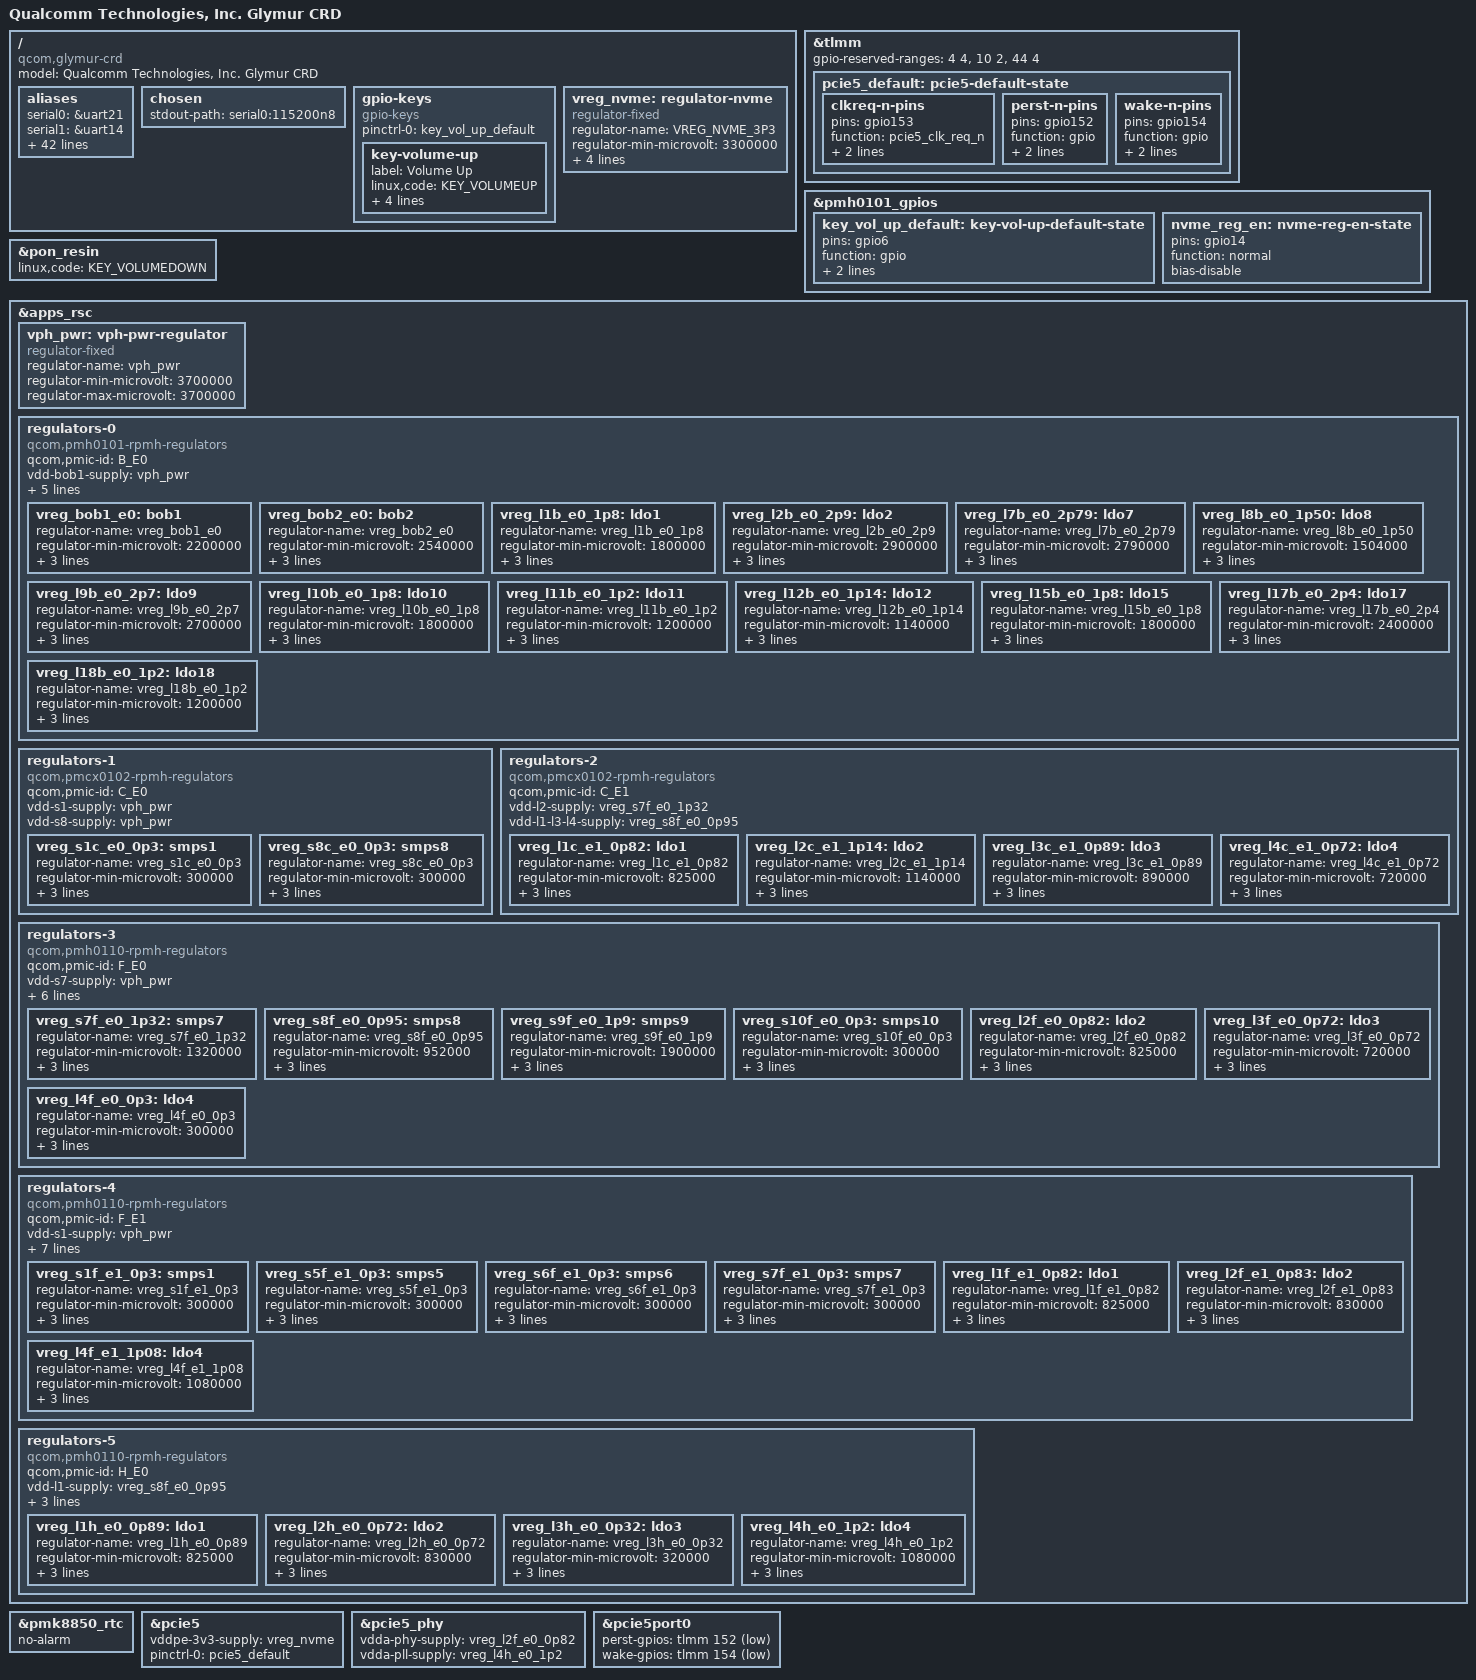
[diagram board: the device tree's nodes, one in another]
// SPDX-License-Identifier: GPL-2.0-only
/*
 * Copyright (c) Qualcomm Technologies, Inc. and/or its subsidiaries.
 */

/dts-v1/;

#include "glymur.dtsi"
#include "glymur-pmics.dtsi"
#include <dt-bindings/regulator/qcom,rpmh-regulator.h>

/ {
	model = "Qualcomm Technologies, Inc. Glymur CRD";
	compatible = "qcom,glymur-crd", "qcom,glymur";

	aliases {
		serial0 = &uart21;
		serial1 = &uart14;
		i2c0 = &i2c16;
		i2c1 = &i2c17;
		i2c2 = &i2c18;
		i2c3 = &i2c19;
		i2c4 = &i2c20;
		i2c5 = &i2c22;
		i2c6 = &i2c23;
		i2c7 = &i2c8;
		i2c8 = &i2c9;
		i2c9 = &i2c10;
		i2c10 = &i2c11;
		i2c11 = &i2c12;
		i2c12 = &i2c13;
		i2c13 = &i2c15;
		i2c14 = &i2c0;
		i2c15 = &i2c1;
		i2c16 = &i2c2;
		i2c17 = &i2c3;
		i2c18 = &i2c4;
		i2c19 = &i2c5;
		i2c20 = &i2c6;
		spi0 = &spi16;
		spi1 = &spi17;
		spi2 = &spi18;
		spi3 = &spi19;
		spi4 = &spi20;
		spi5 = &spi22;
		spi6 = &spi23;
		spi7 = &spi8;
		spi8 = &spi9;
		spi9 = &spi10;
		spi10 = &spi11;
		spi11 = &spi12;
		spi12 = &spi13;
		spi13 = &spi15;
		spi14 = &spi0;
		spi15 = &spi1;
		spi16 = &spi2;
		spi17 = &spi3;
		spi18 = &spi4;
		spi19 = &spi5;
		spi20 = &spi6;
	};

	chosen {
		stdout-path = "serial0:115200n8";
	};

	gpio-keys {
		compatible = "gpio-keys";

		pinctrl-0 = <&key_vol_up_default>;
		pinctrl-names = "default";

		key-volume-up {
			label = "Volume Up";
			linux,code = <KEY_VOLUMEUP>;
			gpios = <&pmh0101_gpios 6 GPIO_ACTIVE_LOW>;
			debounce-interval = <15>;
			linux,can-disable;
			wakeup-source;
		};
	};

	vreg_nvme: regulator-nvme {
		compatible = "regulator-fixed";

		regulator-name = "VREG_NVME_3P3";
		regulator-min-microvolt = <3300000>;
		regulator-max-microvolt = <3300000>;

		gpio = <&pmh0101_gpios 14 GPIO_ACTIVE_HIGH>;
		enable-active-high;

		pinctrl-0 = <&nvme_reg_en>;
		pinctrl-names = "default";
	};
};

&tlmm {
	gpio-reserved-ranges = <4 4>, <10 2>, <44 4>; /*Security SPI (TPM)*/
};

&pmh0101_gpios {
	key_vol_up_default: key-vol-up-default-state {
		pins = "gpio6";
		function = "gpio";
		output-disable;
		bias-pull-up;
	};
};

&pon_resin {
	linux,code = <KEY_VOLUMEDOWN>;
	status = "okay";
};

&apps_rsc {

	vph_pwr: vph-pwr-regulator {
		compatible = "regulator-fixed";
		regulator-name = "vph_pwr";
		regulator-min-microvolt = <3700000>;
		regulator-max-microvolt = <3700000>;
	};

	regulators-0 {
		compatible = "qcom,pmh0101-rpmh-regulators";
		qcom,pmic-id = "B_E0";

		vdd-bob1-supply = <&vph_pwr>;
		vdd-bob2-supply = <&vph_pwr>;
		vdd-l1-l10-l15-supply = <&vreg_s9f_e0_1p9>;
		vdd-l2-l7-l8-l9-l16-supply = <&vreg_bob1_e0>;
		vdd-l11-l12-l18-supply = <&vreg_s7f_e0_1p32>;
		vdd-l17-supply = <&vreg_bob2_e0>;

		vreg_bob1_e0: bob1 {
			regulator-name = "vreg_bob1_e0";
			regulator-min-microvolt = <2200000>;
			regulator-max-microvolt = <4224000>;
			regulator-initial-mode = <RPMH_REGULATOR_MODE_AUTO>;
		};

		vreg_bob2_e0: bob2 {
			regulator-name = "vreg_bob2_e0";
			regulator-min-microvolt = <2540000>;
			regulator-max-microvolt = <3600000>;
			regulator-initial-mode = <RPMH_REGULATOR_MODE_AUTO>;
		};

		vreg_l1b_e0_1p8: ldo1 {
			regulator-name = "vreg_l1b_e0_1p8";
			regulator-min-microvolt = <1800000>;
			regulator-max-microvolt = <1800000>;
			regulator-initial-mode = <RPMH_REGULATOR_MODE_HPM>;
		};

		vreg_l2b_e0_2p9: ldo2 {
			regulator-name = "vreg_l2b_e0_2p9";
			regulator-min-microvolt = <2900000>;
			regulator-max-microvolt = <3300000>;
			regulator-initial-mode = <RPMH_REGULATOR_MODE_HPM>;
		};

		vreg_l7b_e0_2p79: ldo7 {
			regulator-name = "vreg_l7b_e0_2p79";
			regulator-min-microvolt = <2790000>;
			regulator-max-microvolt = <3300000>;
			regulator-initial-mode = <RPMH_REGULATOR_MODE_HPM>;
		};

		vreg_l8b_e0_1p50: ldo8 {
			regulator-name = "vreg_l8b_e0_1p50";
			regulator-min-microvolt = <1504000>;
			regulator-max-microvolt = <3544000>;
			regulator-initial-mode = <RPMH_REGULATOR_MODE_HPM>;
		};

		vreg_l9b_e0_2p7: ldo9 {
			regulator-name = "vreg_l9b_e0_2p7";
			regulator-min-microvolt = <2700000>;
			regulator-max-microvolt = <3300000>;
			regulator-initial-mode = <RPMH_REGULATOR_MODE_HPM>;
		};

		vreg_l10b_e0_1p8: ldo10 {
			regulator-name = "vreg_l10b_e0_1p8";
			regulator-min-microvolt = <1800000>;
			regulator-max-microvolt = <1800000>;
			regulator-initial-mode = <RPMH_REGULATOR_MODE_HPM>;
		};

		vreg_l11b_e0_1p2: ldo11 {
			regulator-name = "vreg_l11b_e0_1p2";
			regulator-min-microvolt = <1200000>;
			regulator-max-microvolt = <1200000>;
			regulator-initial-mode = <RPMH_REGULATOR_MODE_HPM>;
		};

		vreg_l12b_e0_1p14: ldo12 {
			regulator-name = "vreg_l12b_e0_1p14";
			regulator-min-microvolt = <1140000>;
			regulator-max-microvolt = <1260000>;
			regulator-initial-mode = <RPMH_REGULATOR_MODE_HPM>;
		};

		vreg_l15b_e0_1p8: ldo15 {
			regulator-name = "vreg_l15b_e0_1p8";
			regulator-min-microvolt = <1800000>;
			regulator-max-microvolt = <1800000>;
			regulator-initial-mode = <RPMH_REGULATOR_MODE_HPM>;
		};

		vreg_l17b_e0_2p4: ldo17 {
			regulator-name = "vreg_l17b_e0_2p4";
			regulator-min-microvolt = <2400000>;
			regulator-max-microvolt = <2700000>;
			regulator-initial-mode = <RPMH_REGULATOR_MODE_HPM>;
		};

		vreg_l18b_e0_1p2: ldo18 {
			regulator-name = "vreg_l18b_e0_1p2";
			regulator-min-microvolt = <1200000>;
			regulator-max-microvolt = <1200000>;
			regulator-initial-mode = <RPMH_REGULATOR_MODE_HPM>;
		};
	};

	regulators-1 {
		compatible = "qcom,pmcx0102-rpmh-regulators";
		qcom,pmic-id = "C_E0";
		vdd-s1-supply = <&vph_pwr>;
		vdd-s8-supply = <&vph_pwr>;

		vreg_s1c_e0_0p3: smps1 {
			regulator-name = "vreg_s1c_e0_0p3";
			regulator-min-microvolt = <300000>;
			regulator-max-microvolt = <1200000>;
			regulator-initial-mode = <RPMH_REGULATOR_MODE_HPM>;
		};

		vreg_s8c_e0_0p3: smps8 {
			regulator-name = "vreg_s8c_e0_0p3";
			regulator-min-microvolt = <300000>;
			regulator-max-microvolt = <1200000>;
			regulator-initial-mode = <RPMH_REGULATOR_MODE_HPM>;
		};
	};

	regulators-2 {
		compatible = "qcom,pmcx0102-rpmh-regulators";
		qcom,pmic-id = "C_E1";

		vdd-l2-supply = <&vreg_s7f_e0_1p32>;
		vdd-l1-l3-l4-supply = <&vreg_s8f_e0_0p95>;

		vreg_l1c_e1_0p82: ldo1 {
			regulator-name = "vreg_l1c_e1_0p82";
			regulator-min-microvolt = <825000>;
			regulator-max-microvolt = <958000>;
			regulator-initial-mode = <RPMH_REGULATOR_MODE_HPM>;
		};

		vreg_l2c_e1_1p14: ldo2 {
			regulator-name = "vreg_l2c_e1_1p14";
			regulator-min-microvolt = <1140000>;
			regulator-max-microvolt = <1300000>;
			regulator-initial-mode = <RPMH_REGULATOR_MODE_HPM>;
		};

		vreg_l3c_e1_0p89: ldo3 {
			regulator-name = "vreg_l3c_e1_0p89";
			regulator-min-microvolt = <890000>;
			regulator-max-microvolt = <980000>;
			regulator-initial-mode = <RPMH_REGULATOR_MODE_HPM>;
		};

		vreg_l4c_e1_0p72: ldo4 {
			regulator-name = "vreg_l4c_e1_0p72";
			regulator-min-microvolt = <720000>;
			regulator-max-microvolt = <980000>;
			regulator-initial-mode = <RPMH_REGULATOR_MODE_HPM>;
		};
	};

	regulators-3 {
		compatible = "qcom,pmh0110-rpmh-regulators";
		qcom,pmic-id = "F_E0";
		vdd-s7-supply = <&vph_pwr>;
		vdd-s8-supply = <&vph_pwr>;
		vdd-s9-supply = <&vph_pwr>;
		vdd-s10-supply = <&vph_pwr>;
		vdd-l2-supply = <&vreg_s8f_e0_0p95>;
		vdd-l3-supply = <&vreg_s8f_e0_0p95>;
		vdd-l4-supply = <&vreg_s8f_e0_0p95>;

		vreg_s7f_e0_1p32: smps7 {
			regulator-name = "vreg_s7f_e0_1p32";
			regulator-min-microvolt = <1320000>;
			regulator-max-microvolt = <1352000>;
			regulator-initial-mode = <RPMH_REGULATOR_MODE_HPM>;
		};

		vreg_s8f_e0_0p95: smps8 {
			regulator-name = "vreg_s8f_e0_0p95";
			regulator-min-microvolt = <952000>;
			regulator-max-microvolt = <1200000>;
			regulator-initial-mode = <RPMH_REGULATOR_MODE_HPM>;
		};

		vreg_s9f_e0_1p9: smps9 {
			regulator-name = "vreg_s9f_e0_1p9";
			regulator-min-microvolt = <1900000>;
			regulator-max-microvolt = <2000000>;
			regulator-initial-mode = <RPMH_REGULATOR_MODE_HPM>;
		};

		vreg_s10f_e0_0p3: smps10 {
			regulator-name = "vreg_s10f_e0_0p3";
			regulator-min-microvolt = <300000>;
			regulator-max-microvolt = <1200000>;
			regulator-initial-mode = <RPMH_REGULATOR_MODE_HPM>;
		};

		vreg_l2f_e0_0p82: ldo2 {
			regulator-name = "vreg_l2f_e0_0p82";
			regulator-min-microvolt = <825000>;
			regulator-max-microvolt = <980000>;
			regulator-initial-mode = <RPMH_REGULATOR_MODE_HPM>;
		};

		vreg_l3f_e0_0p72: ldo3 {
			regulator-name = "vreg_l3f_e0_0p72";
			regulator-min-microvolt = <720000>;
			regulator-max-microvolt = <980000>;
			regulator-initial-mode = <RPMH_REGULATOR_MODE_HPM>;
		};

		vreg_l4f_e0_0p3: ldo4 {
			regulator-name = "vreg_l4f_e0_0p3";
			regulator-min-microvolt = <300000>;
			regulator-max-microvolt = <1200000>;
			regulator-initial-mode = <RPMH_REGULATOR_MODE_HPM>;
		};
	};

	regulators-4 {
		compatible = "qcom,pmh0110-rpmh-regulators";
		qcom,pmic-id = "F_E1";
		vdd-s1-supply = <&vph_pwr>;
		vdd-s3-supply = <&vph_pwr>;
		vdd-s5-supply = <&vph_pwr>;
		vdd-s6-supply = <&vph_pwr>;
		vdd-s7-supply = <&vph_pwr>;
		vdd-l1-supply = <&vreg_s8f_e0_0p95>;
		vdd-l2-supply = <&vreg_s8f_e0_0p95>;
		vdd-l4-supply = <&vreg_s8f_e0_0p95>;

		vreg_s1f_e1_0p3: smps1 {
			regulator-name = "vreg_s1f_e1_0p3";
			regulator-min-microvolt = <300000>;
			regulator-max-microvolt = <1200000>;
			regulator-initial-mode = <RPMH_REGULATOR_MODE_HPM>;
		};

		vreg_s5f_e1_0p3: smps5 {
			regulator-name = "vreg_s5f_e1_0p3";
			regulator-min-microvolt = <300000>;
			regulator-max-microvolt = <1200000>;
			regulator-initial-mode = <RPMH_REGULATOR_MODE_HPM>;
		};

		vreg_s6f_e1_0p3: smps6 {
			regulator-name = "vreg_s6f_e1_0p3";
			regulator-min-microvolt = <300000>;
			regulator-max-microvolt = <1200000>;
			regulator-initial-mode = <RPMH_REGULATOR_MODE_HPM>;
		};

		vreg_s7f_e1_0p3: smps7 {
			regulator-name = "vreg_s7f_e1_0p3";
			regulator-min-microvolt = <300000>;
			regulator-max-microvolt = <1200000>;
			regulator-initial-mode = <RPMH_REGULATOR_MODE_HPM>;
		};

		vreg_l1f_e1_0p82: ldo1 {
			regulator-name = "vreg_l1f_e1_0p82";
			regulator-min-microvolt = <825000>;
			regulator-max-microvolt = <950000>;
			regulator-initial-mode = <RPMH_REGULATOR_MODE_HPM>;
		};

		vreg_l2f_e1_0p83: ldo2 {
			regulator-name = "vreg_l2f_e1_0p83";
			regulator-min-microvolt = <830000>;
			regulator-max-microvolt = <920000>;
			regulator-initial-mode = <RPMH_REGULATOR_MODE_HPM>;
		};

		vreg_l4f_e1_1p08: ldo4 {
			regulator-name = "vreg_l4f_e1_1p08";
			regulator-min-microvolt = <1080000>;
			regulator-max-microvolt = <1320000>;
			regulator-initial-mode = <RPMH_REGULATOR_MODE_HPM>;
		};
	};

	regulators-5 {
		compatible = "qcom,pmh0110-rpmh-regulators";
		qcom,pmic-id = "H_E0";

		vdd-l1-supply = <&vreg_s8f_e0_0p95>;
		vdd-l2-supply = <&vreg_s8f_e0_0p95>;
		vdd-l3-supply = <&vreg_s9f_e0_1p9>;
		vdd-l4-supply = <&vreg_s7f_e0_1p32>;

		vreg_l1h_e0_0p89: ldo1 {
			regulator-name = "vreg_l1h_e0_0p89";
			regulator-min-microvolt = <825000>;
			regulator-max-microvolt = <950000>;
			regulator-initial-mode = <RPMH_REGULATOR_MODE_HPM>;
		};

		vreg_l2h_e0_0p72: ldo2 {
			regulator-name = "vreg_l2h_e0_0p72";
			regulator-min-microvolt = <830000>;
			regulator-max-microvolt = <920000>;
			regulator-initial-mode = <RPMH_REGULATOR_MODE_HPM>;
		};

		vreg_l3h_e0_0p32: ldo3 {
			regulator-name = "vreg_l3h_e0_0p32";
			regulator-min-microvolt = <320000>;
			regulator-max-microvolt = <2000000>;
			regulator-initial-mode = <RPMH_REGULATOR_MODE_HPM>;
		};

		vreg_l4h_e0_1p2: ldo4 {
			regulator-name = "vreg_l4h_e0_1p2";
			regulator-min-microvolt = <1080000>;
			regulator-max-microvolt = <1320000>;
			regulator-initial-mode = <RPMH_REGULATOR_MODE_HPM>;
		};
	};
};

&pmk8850_rtc {
	no-alarm;
};

&pmh0101_gpios {
	nvme_reg_en: nvme-reg-en-state {
		pins = "gpio14";
		function = "normal";
		bias-disable;
	};
};

&tlmm {
	pcie5_default: pcie5-default-state {
		clkreq-n-pins {
			pins = "gpio153";
			function = "pcie5_clk_req_n";
			drive-strength = <2>;
			bias-pull-up;
		};

		perst-n-pins {
			pins = "gpio152";
			function = "gpio";
			drive-strength = <2>;
			bias-disable;
		};

		wake-n-pins {
			pins = "gpio154";
			function = "gpio";
			drive-strength = <2>;
			bias-pull-up;
		};
	};
};

&pcie5 {
	vddpe-3v3-supply = <&vreg_nvme>;

	pinctrl-0 = <&pcie5_default>;
	pinctrl-names = "default";

	status = "okay";
};

&pcie5_phy {
	vdda-phy-supply = <&vreg_l2f_e0_0p82>;
	vdda-pll-supply = <&vreg_l4h_e0_1p2>;

	status = "okay";
};

&pcie5port0 {
	perst-gpios = <&tlmm 152 GPIO_ACTIVE_LOW>;
	wake-gpios = <&tlmm 154 GPIO_ACTIVE_LOW>;
};
